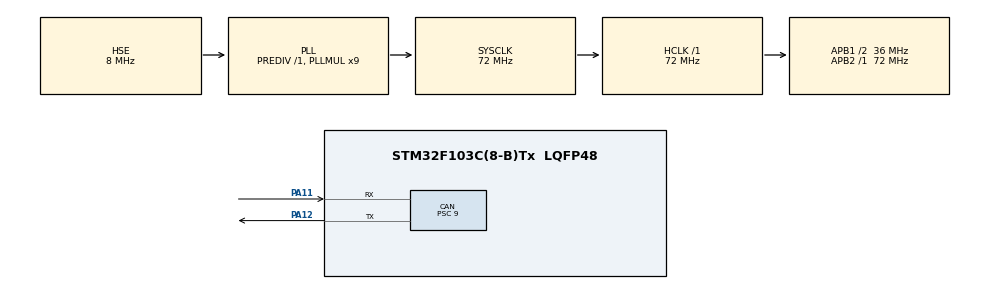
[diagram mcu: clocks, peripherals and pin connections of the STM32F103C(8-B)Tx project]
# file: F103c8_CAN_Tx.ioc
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Mcu.Family=STM32F1
RCC.PLLSourceVirtual=RCC_PLLSOURCE_HSE
NVIC.CAN1_RX1_IRQn=true\:0\:0\:false\:false\:true\:true\:true
PD1-OSC_OUT.Mode=HSE-External-Oscillator
CAN.CalculateBaudRate=1000000
PA11.Mode=CAN_Activate
CAN.SJW=CAN_SJW_1TQ
PD0-OSC_IN.Signal=RCC_OSC_IN
RCC.APB1CLKDivider=RCC_HCLK_DIV2
VP_SYS_VS_ND.Mode=No_Debug
CAN.CalculateTimeBit=1000.00
RCC.SYSCLKSource=RCC_SYSCLKSOURCE_PLLCLK
ProjectManager.StackSize=0x400
PD1-OSC_OUT.Signal=RCC_OSC_OUT
PA12.Signal=CAN_TX
CAN.BS1=CAN_BS1_2TQ
CAN.Prescaler=9
ProjectManager.TargetToolchain=STM32CubeIDE
RCC.HCLKFreq_Value=72000000
RCC.APB2TimFreq_Value=72000000
RCC.USBFreq_Value=72000000
RCC.AHBFreq_Value=72000000
PD0-OSC_IN.Mode=HSE-External-Oscillator
board=custom
RCC.PLLMUL=RCC_PLL_MUL9
RCC.APB2Freq_Value=72000000
Mcu.Name=STM32F103C(8-B)Tx
CAN.CalculateTimeQuantum=250.0
RCC.SYSCLKFreq_VALUE=72000000
Mcu.Package=LQFP48
PA12.Mode=CAN_Activate
PA11.Signal=CAN_RX
ProjectManager.HeapSize=0x200
NVIC.PriorityGroup=NVIC_PRIORITYGROUP_4
RCC.APB1TimFreq_Value=72000000
RCC.APB1Freq_Value=36000000

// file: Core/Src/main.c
/* USER CODE BEGIN Header */
/**
  ******************************************************************************
  * @file           : main.c
  * @brief          : Main program body
  ******************************************************************************
  * @attention
  *
  * <h2><center>&copy; Copyright (c) 2023 STMicroelectronics.
  * All rights reserved.</center></h2>
  *
  * This software component is licensed by ST under BSD 3-Clause license,
  * the "License"; You may not use this file except in compliance with the
  * License. You may obtain a copy of the License at:
  *                        opensource.org/licenses/BSD-3-Clause
  *
  ******************************************************************************
  */
/* USER CODE END Header */
#include "main.h"
#include "can.h"
#include "gpio.h"

/* USER CODE BEGIN PV */

	CAN_TxHeaderTypeDef CanHeader;
	uint8_t  TxData[8];
	uint32_t TxMailbox;
	uint8_t  TxData1[8];

/* USER CODE END PV */

void SystemClock_Config(void);

int main(void)
{

  /* MCU Configuration--------------------------------------------------------*/

  /* Reset of all peripherals, Initializes the Flash interface and the Systick. */
  HAL_Init();

  /* Configure the system clock */
  SystemClock_Config();

  /* Initialize all configured peripherals */
  MX_GPIO_Init();
  MX_CAN_Init();

  /* Infinite loop */
  while (1)
  {

    /* USER CODE BEGIN 3 */

	  	TxData[0] = 1;
	  	TxData[1] = 2;
	  	TxData[2] = 3;
	  	TxData[3] = 4;
	  	CanHeader.StdId = 0x111;
		HAL_CAN_AddTxMessage(&hcan, &CanHeader, TxData, &TxMailbox);
		HAL_Delay(10);

		TxData1[0] = 10;
		TxData1[1] = 20;
		TxData1[2] = 30;
		TxData1[3] = 40;
		TxData1[4] = 50;
		TxData1[5] = 60;
		TxData1[6] = 70;
		TxData1[7] = 80;
		CanHeader.StdId = 0x222;
		HAL_CAN_AddTxMessage(&hcan, &CanHeader, TxData1, &TxMailbox);
		HAL_Delay(10);

  }
  /* USER CODE END 3 */
}

void SystemClock_Config(void)
{
  RCC_OscInitTypeDef RCC_OscInitStruct = {0};
  RCC_ClkInitTypeDef RCC_ClkInitStruct = {0};

  /** Initializes the RCC Oscillators according to the specified parameters
  * in the RCC_OscInitTypeDef structure.
  */
  RCC_OscInitStruct.OscillatorType = RCC_OSCILLATORTYPE_HSE;
  RCC_OscInitStruct.HSEState = RCC_HSE_ON;
  RCC_OscInitStruct.HSEPredivValue = RCC_HSE_PREDIV_DIV1;
  RCC_OscInitStruct.HSIState = RCC_HSI_ON;
  RCC_OscInitStruct.PLL.PLLState = RCC_PLL_ON;
  RCC_OscInitStruct.PLL.PLLSource = RCC_PLLSOURCE_HSE;
  RCC_OscInitStruct.PLL.PLLMUL = RCC_PLL_MUL9;
  if (HAL_RCC_OscConfig(&RCC_OscInitStruct) != HAL_OK)
  {
    Error_Handler();
  }
  /** Initializes the CPU, AHB and APB buses clocks
  */
  RCC_ClkInitStruct.ClockType = RCC_CLOCKTYPE_HCLK|RCC_CLOCKTYPE_SYSCLK
                              |RCC_CLOCKTYPE_PCLK1|RCC_CLOCKTYPE_PCLK2;
  RCC_ClkInitStruct.SYSCLKSource = RCC_SYSCLKSOURCE_PLLCLK;
  RCC_ClkInitStruct.AHBCLKDivider = RCC_SYSCLK_DIV1;
  RCC_ClkInitStruct.APB1CLKDivider = RCC_HCLK_DIV2;
  RCC_ClkInitStruct.APB2CLKDivider = RCC_HCLK_DIV1;

  if (HAL_RCC_ClockConfig(&RCC_ClkInitStruct, FLASH_LATENCY_2) != HAL_OK)
  {
    Error_Handler();
  }
}

void Error_Handler(void)
{
  __disable_irq();
  while (1)
  {
  }
}

/************************ (C) COPYRIGHT STMicroelectronics *****END OF FILE****/
